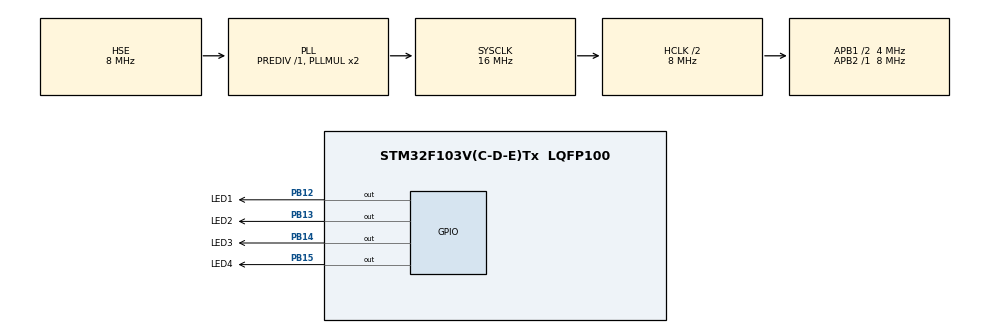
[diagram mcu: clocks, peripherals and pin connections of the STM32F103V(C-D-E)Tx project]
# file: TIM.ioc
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Mcu.Family=STM32F1
Mcu.Name=STM32F103V(C-D-E)Tx
Mcu.Package=LQFP100
NVIC.PriorityGroup=NVIC_PRIORITYGROUP_4
NVIC.TIM3_IRQn=true\:0\:0\:false\:false\:true\:true\:true
OSC_IN.Mode=HSE-External-Oscillator
OSC_IN.Signal=RCC_OSC_IN
OSC_OUT.Mode=HSE-External-Oscillator
OSC_OUT.Signal=RCC_OSC_OUT
PB12.GPIO_Label=LED1
PB12.Signal=GPIO_Output
PB13.GPIO_Label=LED2
PB13.Signal=GPIO_Output
PB14.GPIO_Label=LED3
PB14.Signal=GPIO_Output
PB15.GPIO_Label=LED4
PB15.Signal=GPIO_Output
ProjectManager.HeapSize=0x400
ProjectManager.StackSize=0x200
ProjectManager.TargetToolchain=STM32CubeIDE
RCC.AHBCLKDivider=RCC_SYSCLK_DIV2
RCC.AHBFreq_Value=8000000
RCC.APB1CLKDivider=RCC_HCLK_DIV2
RCC.APB1Freq_Value=4000000
RCC.APB1TimFreq_Value=8000000
RCC.APB2Freq_Value=8000000
RCC.APB2TimFreq_Value=8000000
RCC.HCLKFreq_Value=8000000
RCC.PLLSourceVirtual=RCC_PLLSOURCE_HSE
RCC.SYSCLKFreq_VALUE=16000000
RCC.SYSCLKSource=RCC_SYSCLKSOURCE_PLLCLK
RCC.USBFreq_Value=16000000
TIM3.Period=8000-1
TIM3.Prescaler=1000-1
TIM3.TIM_MasterOutputTrigger=TIM_TRGO_UPDATE
VP_TIM3_VS_ClockSourceINT.Mode=Internal
board=TIM

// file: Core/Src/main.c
/**
  ******************************************************************************
  * File Name          : main.c
  * Description        : Main program body
  ******************************************************************************
  *
  * COPYRIGHT(c) 2020 STMicroelectronics
  *
  * Redistribution and use in source and binary forms, with or without modification,
  * are permitted provided that the following conditions are met:
  *   1. Redistributions of source code must retain the above copyright notice,
  *      this list of conditions and the following disclaimer.
  *   2. Redistributions in binary form must reproduce the above copyright notice,
  *      this list of conditions and the following disclaimer in the documentation
  *      and/or other materials provided with the distribution.
  *   3. Neither the name of STMicroelectronics nor the names of its contributors
  *      may be used to endorse or promote products derived from this software
  *      without specific prior written permission.
  *
  * THIS SOFTWARE IS PROVIDED BY THE COPYRIGHT HOLDERS AND CONTRIBUTORS "AS IS"
  * AND ANY EXPRESS OR IMPLIED WARRANTIES, INCLUDING, BUT NOT LIMITED TO, THE
  * IMPLIED WARRANTIES OF MERCHANTABILITY AND FITNESS FOR A PARTICULAR PURPOSE ARE
  * DISCLAIMED. IN NO EVENT SHALL THE COPYRIGHT HOLDER OR CONTRIBUTORS BE LIABLE
  * FOR ANY DIRECT, INDIRECT, INCIDENTAL, SPECIAL, EXEMPLARY, OR CONSEQUENTIAL
  * DAMAGES (INCLUDING, BUT NOT LIMITED TO, PROCUREMENT OF SUBSTITUTE GOODS OR
  * SERVICES; LOSS OF USE, DATA, OR PROFITS; OR BUSINESS INTERRUPTION) HOWEVER
  * CAUSED AND ON ANY THEORY OF LIABILITY, WHETHER IN CONTRACT, STRICT LIABILITY,
  * OR TORT (INCLUDING NEGLIGENCE OR OTHERWISE) ARISING IN ANY WAY OUT OF THE USE
  * OF THIS SOFTWARE, EVEN IF ADVISED OF THE POSSIBILITY OF SUCH DAMAGE.
  *
  ******************************************************************************
  */
#include "stm32f1xx_hal.h"
#include "tim.h"
#include "gpio.h"

/* USER CODE BEGIN PV */
/* Private variables ---------------------------------------------------------*/

/* USER CODE END PV */

void SystemClock_Config(void);

/* USER CODE BEGIN PFP */
/* Private function prototypes -----------------------------------------------*/

/* USER CODE END PFP */

int main(void)
{

  /* MCU Configuration----------------------------------------------------------*/

  /* Reset of all peripherals, Initializes the Flash interface and the Systick. */
  HAL_Init();

  /* Configure the system clock */
  SystemClock_Config();

  /* Initialize all configured peripherals */
  MX_GPIO_Init();
  SystemClock_Config();
  MX_TIM3_Init();

  /* USER CODE BEGIN 2 */
  HAL_TIM_Base_Start_IT(&htim3);
  /* USER CODE END 2 */

  /* Infinite loop */
  while (1)
  {

  }

}

/** System Clock Configuration
*/
void SystemClock_Config(void)
{

  RCC_OscInitTypeDef RCC_OscInitStruct;
  RCC_ClkInitTypeDef RCC_ClkInitStruct;

  RCC_OscInitStruct.OscillatorType = RCC_OSCILLATORTYPE_HSE;
  RCC_OscInitStruct.HSEState = RCC_HSE_ON;
  RCC_OscInitStruct.HSEPredivValue = RCC_HSE_PREDIV_DIV1;
  RCC_OscInitStruct.HSIState = RCC_HSI_ON;
  RCC_OscInitStruct.PLL.PLLState = RCC_PLL_ON;
  RCC_OscInitStruct.PLL.PLLSource = RCC_PLLSOURCE_HSE;
  RCC_OscInitStruct.PLL.PLLMUL = RCC_PLL_MUL2;
  HAL_RCC_OscConfig(&RCC_OscInitStruct);

  RCC_ClkInitStruct.ClockType = RCC_CLOCKTYPE_HCLK|RCC_CLOCKTYPE_SYSCLK
                              |RCC_CLOCKTYPE_PCLK1|RCC_CLOCKTYPE_PCLK2;
  RCC_ClkInitStruct.SYSCLKSource = RCC_SYSCLKSOURCE_PLLCLK;
  RCC_ClkInitStruct.AHBCLKDivider = RCC_SYSCLK_DIV2;
  RCC_ClkInitStruct.APB1CLKDivider = RCC_HCLK_DIV2;
  RCC_ClkInitStruct.APB2CLKDivider = RCC_HCLK_DIV1;
  HAL_RCC_ClockConfig(&RCC_ClkInitStruct, FLASH_LATENCY_0);

  HAL_SYSTICK_Config(HAL_RCC_GetHCLKFreq()/1000);

  HAL_SYSTICK_CLKSourceConfig(SYSTICK_CLKSOURCE_HCLK);

  /* SysTick_IRQn interrupt configuration */
  HAL_NVIC_SetPriority(SysTick_IRQn, 0, 0);
}

/* USER CODE BEGIN 4 */
void HAL_TIM_PeriodElapsedCallback(TIM_HandleTypeDef *htim)
{
	if (htim->Instance == TIM3)
	{
		/* Toggle LED */
		HAL_GPIO_TogglePin(GPIOB, GPIO_PIN_12);
		HAL_GPIO_TogglePin(GPIOB, GPIO_PIN_13);
		HAL_GPIO_TogglePin(GPIOB, GPIO_PIN_14);
		HAL_GPIO_TogglePin(GPIOB, GPIO_PIN_15);
	}
}
/* USER CODE END 4 */

/************************ (C) COPYRIGHT STMicroelectronics *****END OF FILE****/
